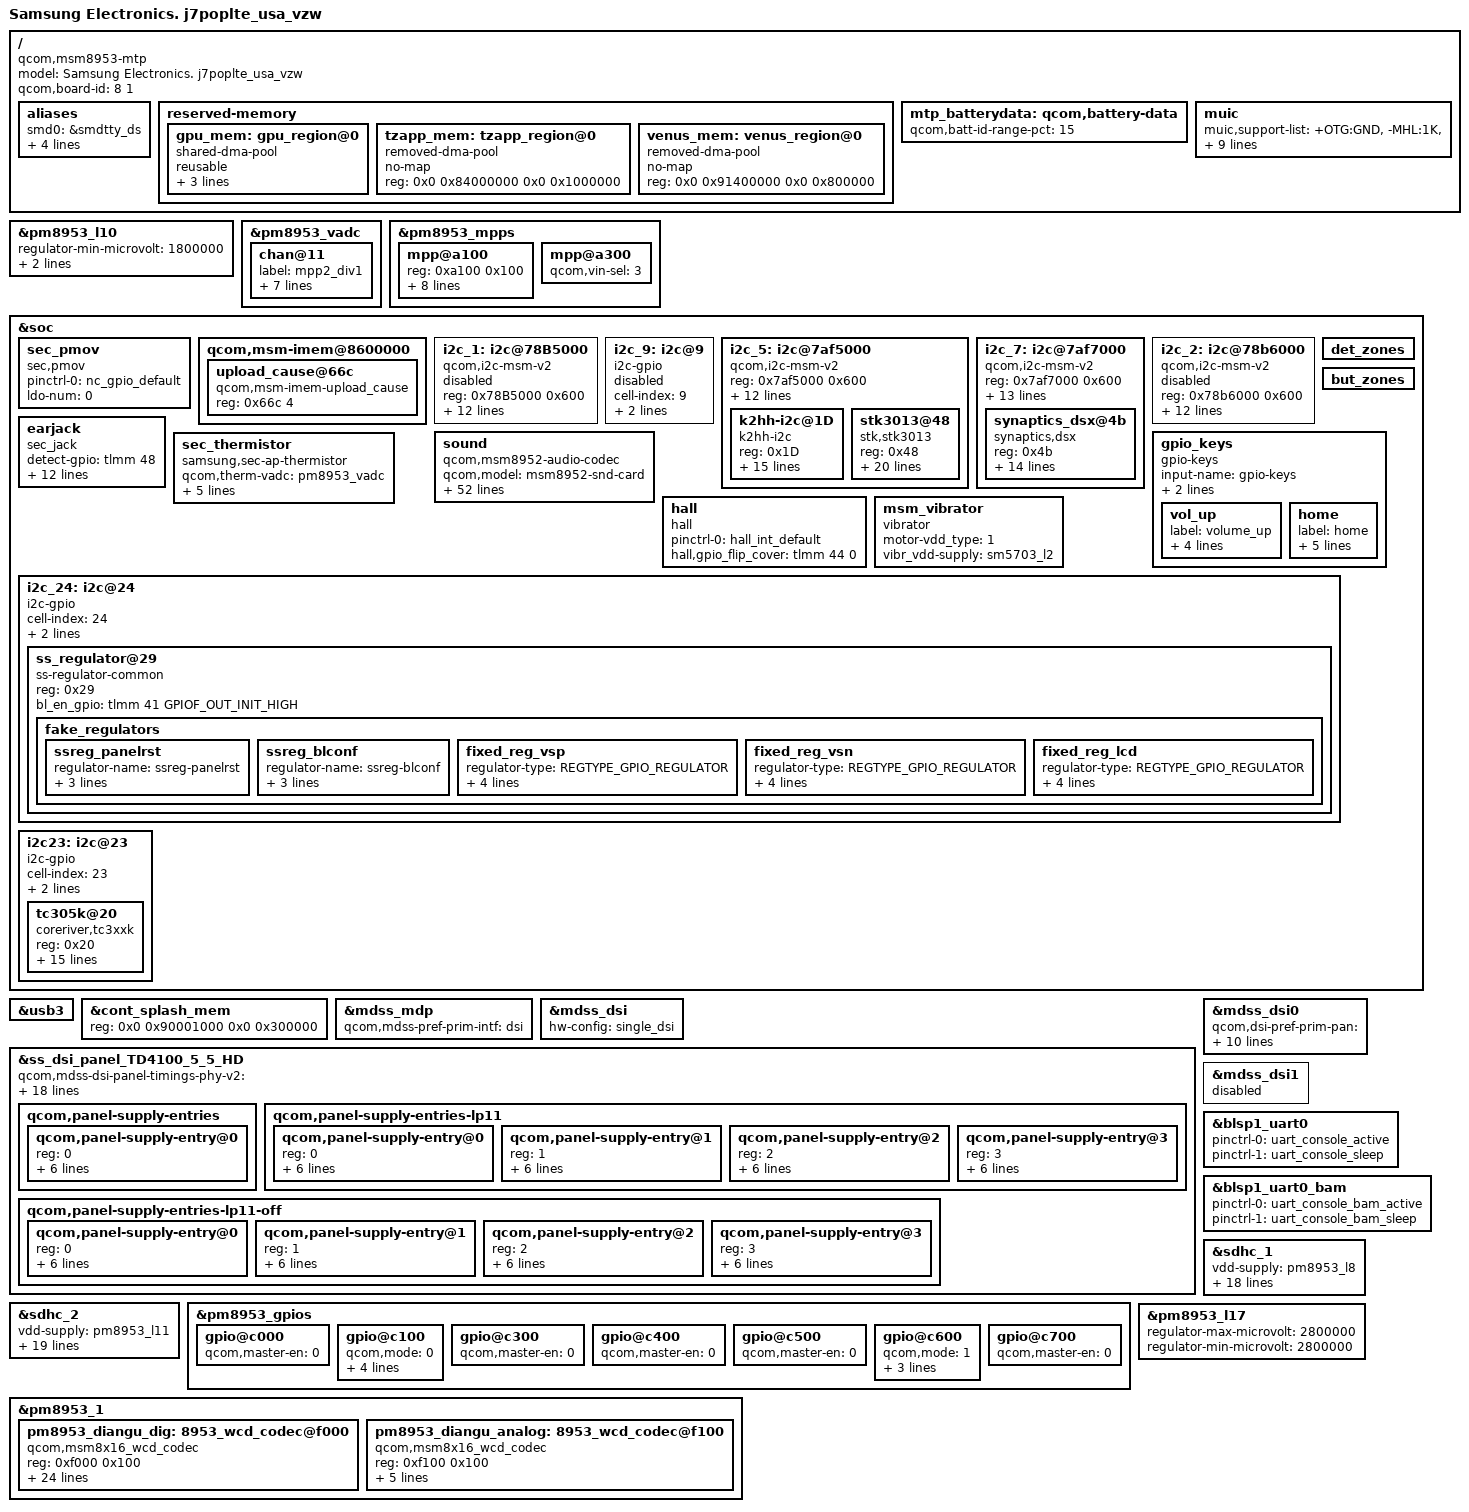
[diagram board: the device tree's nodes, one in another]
/*
 * Copyright (c) 2015, The Linux Foundation. All rights reserved.
 *
 * This program is free software; you can redistribute it and/or modify
 * it under the terms of the GNU General Public License version 2 and
 * only version 2 as published by the Free Software Foundation.
 *
 * This program is distributed in the hope that it will be useful,
 * but WITHOUT ANY WARRANTY; without even the implied warranty of
 * MERCHANTABILITY or FITNESS FOR A PARTICULAR PURPOSE.  See the
 * GNU General Public License for more details.
 */

/dts-v1/;

#include "../../qcom/msm8953.dtsi"
#include "msm-sec-audio.dtsi"
#include "msm8953-sec-common.dtsi"
#include "msm8953-sec-j7poplte_usa_vzw-pinctrl-r01.dtsi"
#include "msm8953-j7poplte_usa_vzw-sm5703.dtsi"
#include "msm8953-sec-j7poplte-battery-common-r01.dtsi"
#include "msm8953-camera-sensor-j7pop-usa_vzw-r01.dtsi"
#define GPIOF_DIR_OUT   (0 << 0)
#define GPIOF_INIT_HIGH (1 << 1)
#define GPIOF_OUT_INIT_HIGH     (GPIOF_DIR_OUT | GPIOF_INIT_HIGH)

#define REGTYPE_PANEL_RESET	0 /* control display reset */
#define REGTYPE_BL_CONFIG	1 /* BLIC initial configuration via I2c */
#define REGTYPE_GPIO_REGULATOR	2 /* GPIO regulator */
/ {
	model = "Samsung Electronics. j7poplte_usa_vzw";
	compatible = "qcom,msm8953-mtp", "qcom,msm8953", "qcom,mtp";
	qcom,board-id= <8 1>;
	aliases {
		/delete-property/ spi3;

		smd0 = &smdtty_ds;
		i2c1 = &i2c_1;
		i2c5 = &i2c_5;
		i2c7 = &i2c_7;
		i2c8 = &i2c_8;
	};

	reserved-memory {
		/delete-node/ gpu_region@0;
		gpu_mem: gpu_region@0 {
			compatible = "shared-dma-pool";
			reusable;
			alloc-ranges = <0x0 0x90000000 0x0 0x10000000>;
			alignment = <0 0x400000>;
			size = <0 0x800000>;
		};

		/delete-node/ tzapp_region@0;
		tzapp_mem: tzapp_region@0 {
			compatible = "removed-dma-pool";
			no-map;
			reg = <0x0 0x84000000 0x0 0x1000000>;
		};

		/delete-node/ venus_region@0;
		venus_mem: venus_region@0 {
			compatible = "removed-dma-pool";
			no-map;
			reg = <0x0 0x91400000 0x0 0x800000>;
		};
	};
};

&pm8953_l10 {
	status = "okay";
	regulator-min-microvolt = <1800000>;
	regulator-max-microvolt = <1800000>;
	qcom,init-voltage = <1800000>;
};

&pm8953_vadc {
	chan@11 {
		label = "mpp2_div1";
		reg = <0x11>;
		qcom,decimation = <0>;
		qcom,pre-div-channel-scaling = <0>;
		qcom,calibration-type = "absolute";
		qcom,scale-function = <0>;
		qcom,hw-settle-time = <5>;
		qcom,fast-avg-setup = <0>;
	};
};

&pm8953_mpps {
	mpp@a100 {
		reg = <0xa100 0x100>;
		qcom,pin-num = <2>;
		status = "okay";
		qcom,mode = <4>; /* AIN input */
		qcom,invert = <0>; /* Enable MPP */
		qcom,output-type = <0>; /* CMOS */
		qcom,ain-route = <1>; /* AMUX 6 */
		qcom,master-en = <0>;
		qcom,src-sel = <0>; /* Function constant */
		qcom,vin-sel = <3>;
	};
	mpp@a300 {
		qcom,vin-sel = <3>;
		status = "okay";
	};
};

&soc {
	sec_pmov {
		compatible = "sec,pmov";

		pinctrl-names = "default";
		pinctrl-0 = <&nc_gpio_default>;

		ldo-num = <0>;
		/*ldo0-supply = <&pm8953_l17>;
		 ldo1-supply = <&pm8953_lx>; */
	};

	qcom,msm-imem@8600000 {
		upload_cause@66c { /* CONFIG_SEC_DEBUG */
			compatible = "qcom,msm-imem-upload_cause";
			reg = <0x66c 4>;
		};
	};

	i2c_1: i2c@78B5000 { /* BLSP1 QUP0 */
		compatible = "qcom,i2c-msm-v2";
		#address-cells = <1>;
		#size-cells = <0>;
		reg-names = "qup_phys_addr";
		reg = <0x78B5000 0x600>;
		interrupt-names = "qup_irq";
		interrupts = <0 95 0>;
		qcom,clk-freq-out = <400000>;
		qcom,clk-freq-in  = <19200000>;
		clock-names = "iface_clk", "core_clk";
		clocks = <&clock_gcc clk_gcc_blsp1_ahb_clk>,
			<&clock_gcc clk_gcc_blsp1_qup1_i2c_apps_clk>;

		pinctrl-names = "i2c_active", "i2c_sleep";
		pinctrl-0 = <&i2c_1_active>;
		pinctrl-1 = <&i2c_1_sleep>;
		qcom,noise-rjct-scl = <0>;
		qcom,noise-rjct-sda = <0>;
		qcom,master-id = <86>;
		dmas = <&dma_blsp1 4 64 0x20000020 0x20>,
			<&dma_blsp1 5 32 0x20000020 0x20>;
		dma-names = "tx", "rx";
		status = "disabled";
	};

	i2c_9: i2c@9 { /* SW I2C */
		status = "disabled";
		cell-index = <9>;
		compatible = "i2c-gpio";
		gpios = <&tlmm 16 0 /* sda */
			&tlmm 17 0 /* scl */
		>;
		i2c-gpio,delay-us = <2>;
		#address-cells = <1>;
		#size-cells = <0>;
	};

	i2c_5: i2c@7af5000 { /* BLSP2 QUP1 */
		compatible = "qcom,i2c-msm-v2";
		#address-cells = <1>;
		#size-cells = <0>;
		reg-names = "qup_phys_addr";
		reg = <0x7af5000 0x600>;
		interrupt-names = "qup_irq";
		interrupts = <0 299 0>;
		qcom,clk-freq-out = <400000>;
		qcom,clk-freq-in  = <19200000>;
		clock-names = "iface_clk", "core_clk";
		clocks = <&clock_gcc clk_gcc_blsp2_ahb_clk>,
			<&clock_gcc clk_gcc_blsp2_qup1_i2c_apps_clk>;

		pinctrl-names = "i2c_active", "i2c_sleep";
		pinctrl-0 = <&i2c_5_active>;
		pinctrl-1 = <&i2c_5_sleep>;
		qcom,noise-rjct-scl = <0>;
		qcom,noise-rjct-sda = <0>;
		qcom,master-id = <84>;
		dmas = <&dma_blsp2 4 64 0x20000020 0x20>,
			<&dma_blsp2 5 32 0x20000020 0x20>;
		dma-names = "tx", "rx";

		k2hh-i2c@1D {
			compatible = "k2hh-i2c";
			reg = <0x1D>;
			pinctrl-names = "default", "sleep";
			pinctrl-0 = <&acc_sensor_int_active>;
			pinctrl-1 = <&acc_sensor_int_suspend>;
			interrupt-parent = <&tlmm>;
			interrupts = <42 0>;
			k2hh,irq_gpio = <&tlmm 42 0x00>;
			k2hh,vdd-supply = <&pm8953_l5>;
			k2hh,vio-supply = <&pm8953_l5>;
			k2hh,axis_map_x = <1>;
			k2hh,axis_map_y = <0>;
			k2hh,axis_map_z = <2>;
			k2hh,negate_x = <0>;
			k2hh,negate_y = <1>;
			k2hh,negate_z = <1>;
			k2hh,poll_interval = <100>;
			k2hh,min_interval = <2>;
		};

		stk3013@48 {
			compatible = "stk,stk3013";
			reg = <0x48>;
			pinctrl-names = "default", "sleep";
			pinctrl-0 = <&prox_sensor_int_active>;
			pinctrl-1 = <&prox_sensor_int_suspend>;
			interrupt-parent =  <&tlmm>;
			interrupts = <43 0>;
			stk,vdd-supply = <&sm5703_l3>;
			stk,vio-supply = <&pm8953_l5>;
			stk,irq-gpio = <&tlmm 43 0x00>;
			stk,state-reg = <0x2d>;
			stk,psctrl-reg = <0x71>;
			stk,alsctrl-reg = <0x2A>;
			stk,ledctrl-reg = <0xBF>;
			stk,wait-reg = <0x03>;
			stk,ps-thd-h = <20>;
			stk,ps-thd-l = <13>;
			stk,ps-cancel-thd-h = <10>;
			stk,ps-cancel-thd-l = <7>;
			stk,ps-cal-skip-adc = <10>;
			stk,ps-cal-fail-adc = <20>;
			stk,ps-default-offset = <3>;
			stk,transmittance = <500>;
		};

	};

	i2c_7: i2c@7af7000 { /* BLSP2 QUP3 */
		compatible = "qcom,i2c-msm-v2";
		#address-cells = <1>;
		#size-cells = <0>;
		reg-names = "qup_phys_addr";
		reg = <0x7af7000 0x600>;
		interrupt-names = "qup_irq";
		interrupts = <0 301 0>;
		qcom,master-id = <84>;
		qcom,clk-freq-out = <400000>;
		qcom,clk-freq-in  = <19200000>;
		clock-names = "iface_clk", "core_clk";
		clocks = <&clock_gcc clk_gcc_blsp2_ahb_clk>,
			<&clock_gcc clk_gcc_blsp2_qup3_i2c_apps_clk>;
		pinctrl-names = "i2c_active", "i2c_sleep";
		pinctrl-0 = <&i2c_7_active>;
		pinctrl-1 = <&i2c_7_suspend>;
		qcom,noise-rjct-scl = <0>;
		qcom,noise-rjct-sda = <0>;
		qcom,disable-dma;
		dmas = <&dma_blsp2 8 64 0x20000020 0x20>,
			<&dma_blsp2 9 32 0x20000020 0x20>;
		dma-names = "tx", "rx";
	};

	i2c_2: i2c@78b6000 { /* BLSP1 QUP2 */
		compatible = "qcom,i2c-msm-v2";
		#address-cells = <1>;
		#size-cells = <0>;
		reg-names = "qup_phys_addr";
		reg = <0x78b6000 0x600>;
		interrupt-names = "qup_irq";
		interrupts = <0 96 0>;
		qcom,clk-freq-out = <400000>;
		qcom,clk-freq-in  = <19200000>;
		clock-names = "iface_clk", "core_clk";
		clocks = <&clock_gcc clk_gcc_blsp1_ahb_clk>,
			<&clock_gcc clk_gcc_blsp1_qup2_i2c_apps_clk>;
		pinctrl-names = "i2c_active", "i2c_sleep";
		pinctrl-0 = <&i2c_2_active>;
		pinctrl-1 = <&i2c_2_sleep>;
		qcom,noise-rjct-scl = <0>;
		qcom,noise-rjct-sda = <0>;
		qcom,master-id = <86>;
		dmas = <&dma_blsp1 6 64 0x20000020 0x20>,
			<&dma_blsp1 7 32 0x20000020 0x20>;
		dma-names = "tx", "rx";
		status = "disabled";
	};

	det_zones: det_zones {
		#list-det-cells = <4>;
	};

	but_zones: but_zones {
		#list-but-cells = <3>;
	};

	earjack {
		compatible = "sec_jack";
		detect-gpio = <&tlmm 48 0x0>;
		key-gpio = <&tlmm 141 0x0>;
		det-dbtime = <100>;
		key-dbtime = <30>;

		det-zones-list = <&det_zones 0 10000 10 2>,
				 <&det_zones 910 10000 10 2>,
				 <&det_zones 1900 10000 10 1>,
				 <&det_zones 9999 10000 10 1>;
		but-zones-list = <&but_zones 226 0 310>, /* KEY_MEDIA:226 */
				 <&but_zones 582 311 350>, /* KEY_VOICECOMMAND:582 */
				 <&but_zones 115 351 470>, /* KEY_VOLUMEUP:115 */
				 <&but_zones 114 471 999>; /* KEY_VOLUMEDOWN:114 */

		pinctrl-names = "earjack_gpio_active",
				"earjack_gpio_suspend";
		pinctrl-0 = <&earjack_det_act &earjack_switch_act>;
		pinctrl-1 = <&earjack_det_sus &earjack_switch_sus>;
	};

	sound {
		status = "okay";
		compatible = "qcom,msm8952-audio-codec";
		qcom,model = "msm8952-snd-card";
		reg = <0xc051000 0x4>,
		      <0xc051004 0x4>,
		      <0xc055000 0x4>,
		      <0xc052000 0x4>;
		reg-names = "csr_gp_io_mux_mic_ctl",
			    "csr_gp_io_mux_spkr_ctl",
			    "csr_gp_io_lpaif_pri_pcm_pri_mode_muxsel",
			    "csr_gp_io_mux_quin_ctl";

		qcom,mpp-standalone-mode;
		qcom,mpp-channel-scaling = <2 1 1>;
		qcom,earjack-adc = <&pm8953_mpps 2 0>;
		qcom,earjack-read-vadc = <&pm8953_vadc>;
		qcom,msm-ext-pa = "primary";
		qcom,msm-mclk-freq = <9600000>;
		qcom,msm-hs-micbias-type = "internal";
		qcom,msm-micbias1-ext-cap;
		qcom,msm-micbias2-ext-cap;
		/delete-property/qcom,hdmi-dba-codec-rx;
		/delete-property/qcom,msm-mbhc-hphl-swh;
		/delete-property/qcom,msm-mbhc-gnd-swh;
		/delete-property/qcom,cdc-us-euro-gpios;
		qcom,audio-routing =
			"RX_BIAS", "MCLK",
			"SPK_RX_BIAS", "MCLK",
			"INT_LDO_H", "MCLK",
			"MIC BIAS External", "Handset Mic",
			"MIC BIAS External", "Secondary Mic",
			"AMIC1", "MIC BIAS External",
			"AMIC2", "Headset Mic",
			"AMIC3", "MIC BIAS External";

		qcom,msm-gpios =
			"pri_i2s";
		qcom,pinctrl-names =
			"all_off",
			"pri_i2s_act";
		pinctrl-names =
			"all_off",
			"pri_i2s_act";
		pinctrl-0 = <&cdc_pdm_lines_sus &cdc_pdm_lines_2_sus >;
		pinctrl-1 = <&cdc_pdm_lines_act &cdc_pdm_lines_2_act >;

		asoc-platform = <&pcm0>, <&pcm1>, <&pcm2>, <&voip>, <&voice>,
				<&loopback>, <&compress>, <&hostless>,
				<&afe>, <&lsm>, <&routing>, <&lpa>;
		asoc-platform-names = "msm-pcm-dsp.0", "msm-pcm-dsp.1",
				"msm-pcm-dsp.2", "msm-voip-dsp",
				"msm-pcm-voice", "msm-pcm-loopback",
				"msm-compress-dsp", "msm-pcm-hostless",
				"msm-pcm-afe", "msm-lsm-client",
				"msm-pcm-routing", "msm-pcm-lpa";
		asoc-cpu = <&dai_pri_auxpcm>,
				<&dai_mi2s0>, <&dai_mi2s1>,
				<&dai_mi2s2>, <&dai_mi2s3>,
				<&dai_mi2s5>, <&dai_mi2s6>,
				<&bt_sco_rx>, <&bt_sco_tx>,
				<&int_fm_rx>, <&int_fm_tx>,
				<&afe_pcm_rx>, <&afe_pcm_tx>,
				<&afe_proxy_rx>, <&afe_proxy_tx>,
				<&incall_record_rx>, <&incall_record_tx>,
				<&incall_music_rx>, <&incall_music_2_rx>;
		asoc-cpu-names = "msm-dai-q6-auxpcm.1",
				"msm-dai-q6-mi2s.0", "msm-dai-q6-mi2s.1",
				"msm-dai-q6-mi2s.2", "msm-dai-q6-mi2s.3",
				"msm-dai-q6-mi2s.5", "msm-dai-q6-mi2s.6",
				"msm-dai-q6-dev.12288", "msm-dai-q6-dev.12289",
				"msm-dai-q6-dev.12292", "msm-dai-q6-dev.12293",
				"msm-dai-q6-dev.224", "msm-dai-q6-dev.225",
				"msm-dai-q6-dev.241", "msm-dai-q6-dev.240",
				"msm-dai-q6-dev.32771", "msm-dai-q6-dev.32772",
				"msm-dai-q6-dev.32773", "msm-dai-q6-dev.32770";

		asoc-codec = <&stub_codec>, <&pm8953_diangu_dig>;
		asoc-codec-names = "msm-stub-codec.1", "cajon_codec";
	};

	gpio_keys {
		compatible = "gpio-keys";
		input-name = "gpio-keys";
		pinctrl-names = "tlmm_gpio_key_active","tlmm_gpio_key_suspend";
		pinctrl-0 = <&gpio_key_active>;
		pinctrl-1 = <&gpio_key_suspend>;

		vol_up {
			label = "volume_up";
			gpios = <&tlmm 85 0x1>;
			linux,input-type = <1>;
			linux,code = <115>;
			debounce-interval = <15>;
		};

		home {
			label = "home";
			gpios = <&tlmm 86 0x1>;
			linux,input-type = <1>;
			linux,code = <172>;
			gpio-key,wakeup;
			debounce-interval = <15>;
		};
	};

	sec_thermistor {
		compatible = "samsung,sec-ap-thermistor";
		qcom,therm-vadc = <&pm8953_vadc>;
		status = "okay";
		adc_channel = <19>;
		adc_array = <25977 26022 26068 26113 26158 26204 26246 26289 26332 26375
					26418 26471 26524 26577 26630 26683 26749 26815 26881 26947
					27013 27106 27199 27291 27384 27477 27582 27687 27792 27897
					28002 28113 28224 28335 28446 28558 28674 28790 28906 29023
					29139 29294 29449 29603 29758 29913 30091 30269 30447 30625
					30803 30982 31162 31342 31522 31702 31888 32074 32260 32446
					32632 32829 33026 33224 33421 33618 33841 34064 34286 34509
					34732 34947 35162 35376 35591 35806 36012 36217 36423 36628
					36834 37010 37185 37361 37537 37713 37919 38126 38332 38539
					38745 38892 39038 39185 39331 39478 39628 39779 39930 40081
					40232 40324 40416 40508 40600 40692 40737 40782 40827 40872
					40917>;

		temp_array = <900 890 880 870 860 850 840 830 820 810
			800 790 780 770 760 750 740 730 720 710
			700 690 680 670 660 650 640 630 620 610
			600 590 580 570 560 550 540 530 520 510
			500 490 480 470 460 450 440 430 420 410
			400 390 380 370 360 350 340 330 320 310
			300 290 280 270 260 250 240 230 220 210
			200 190 180 170 160 150 140 130 120 110
			100 90 80 70 60 50 40 30 20 10
			0 (-10) (-20) (-30) (-40) (-50) (-60) (-70) (-80) (-90)
			(-100) (-110) (-120) (-130) (-140) (-150) (-160) (-170) (-180) (-190)
			(-200)>;
	};

	hall {
		compatible = "hall";
		status = "okay";
		pinctrl-names = "default";
		pinctrl-0 = <&hall_int_default>;
		hall,gpio_flip_cover = <&tlmm 44 0>;
	};

	msm_vibrator {
		compatible = "vibrator";
		motor-vdd_type = <1>; /* 0: gpio, 1: pmic */
		vibr_vdd-supply = <&sm5703_l2>;
	};
};

&usb3 {
	/delete-property/ vbus_dwc3-supply;
};

#include "../../qcom/msm8953-mdss-panels.dtsi"
#include "../../../../../../drivers/video/msm/mdss/samsung/TD4100_5_5/dsi_panel_TD4100_5_5_hd_video.dtsi"
#include "../../../../../../drivers/video/msm/mdss/samsung/PBA_BOOTING_HD/dsi_panel_PBA_BOOTING_hd_video.dtsi"

&cont_splash_mem {
	reg = <0x0 0x90001000 0x0 0x300000>; /*720*1280*3=2.76M =>3M*/
};

&mdss_mdp {
	qcom,mdss-pref-prim-intf = "dsi";
};

&mdss_dsi {
	hw-config = "single_dsi";
};
/* Unnecessary values for fixed reuglator,
 * but required by mdss_dsi_get_dt_vreg_data().
 */
#define DEFAULT_FIXED_VAL	0
&ss_dsi_panel_TD4100_5_5_HD {
	qcom,panel-supply-entries {
		#address-cells = <1>;
		#size-cells = <0>;

		/* VDD_LCD_1P8 */

		qcom,panel-supply-entry@0 {
			reg = <0>;
			qcom,supply-name = "vddlcd";
			qcom,supply-min-voltage = <DEFAULT_FIXED_VAL>;
			qcom,supply-max-voltage = <DEFAULT_FIXED_VAL>;
			qcom,supply-enable-load = <DEFAULT_FIXED_VAL>;
			qcom,supply-disable-load = <DEFAULT_FIXED_VAL>;
			qcom,supply-post-on-sleep = <0>;
		};
		/*
		qcom,panel-supply-entry@1 {
			reg = <1>;
			qcom,supply-name = "vddtsp";
			qcom,supply-min-voltage = <DEFAULT_FIXED_VAL>;
			qcom,supply-max-voltage = <DEFAULT_FIXED_VAL>;
			qcom,supply-enable-load = <DEFAULT_FIXED_VAL>;
			qcom,supply-disable-load = <DEFAULT_FIXED_VAL>;
			qcom,supply-post-on-sleep = <3>;
		};
		*/
	};
	qcom,panel-supply-entries-lp11 {
		#address-cells = <1>;
		#size-cells = <0>;

		qcom,panel-supply-entry@0 {
			reg = <0>;
			qcom,supply-name = "blconf";
			qcom,supply-min-voltage = <DEFAULT_FIXED_VAL>;
			qcom,supply-max-voltage = <DEFAULT_FIXED_VAL>;
			qcom,supply-enable-load = <DEFAULT_FIXED_VAL>;
			qcom,supply-disable-load = <DEFAULT_FIXED_VAL>;
			qcom,supply-post-on-sleep = <0>;
		};

		qcom,panel-supply-entry@1 {
			reg = <1>;
			qcom,supply-name = "vsp";
			qcom,supply-min-voltage = <DEFAULT_FIXED_VAL>;
			qcom,supply-max-voltage = <DEFAULT_FIXED_VAL>;
			qcom,supply-enable-load = <DEFAULT_FIXED_VAL>;
			qcom,supply-disable-load = <DEFAULT_FIXED_VAL>;
			qcom,supply-post-on-sleep = <0>;
		};

		qcom,panel-supply-entry@2 {
			reg = <2>;
			qcom,supply-name = "vsn";
			qcom,supply-min-voltage = <DEFAULT_FIXED_VAL>;
			qcom,supply-max-voltage = <DEFAULT_FIXED_VAL>;
			qcom,supply-enable-load = <DEFAULT_FIXED_VAL>;
			qcom,supply-disable-load = <DEFAULT_FIXED_VAL>;
			qcom,supply-post-on-sleep = <6>;
		};

		qcom,panel-supply-entry@3 {
			reg = <3>;
			qcom,supply-name = "panelrst";
			qcom,supply-min-voltage = <DEFAULT_FIXED_VAL>;
			qcom,supply-max-voltage = <DEFAULT_FIXED_VAL>;
			qcom,supply-enable-load = <DEFAULT_FIXED_VAL>;
			qcom,supply-disable-load = <DEFAULT_FIXED_VAL>;
			qcom,supply-post-on-sleep = <0>;
		};
	};

	qcom,panel-supply-entries-lp11-off {
		#address-cells = <1>;
		#size-cells = <0>;

		qcom,panel-supply-entry@0 {
			reg = <0>;
			qcom,supply-name = "panelrst";
			qcom,supply-min-voltage = <DEFAULT_FIXED_VAL>;
			qcom,supply-max-voltage = <DEFAULT_FIXED_VAL>;
			qcom,supply-enable-load = <DEFAULT_FIXED_VAL>;
			qcom,supply-disable-load = <DEFAULT_FIXED_VAL>;
			qcom,supply-post-off-sleep = <1>;
		};

		qcom,panel-supply-entry@1 {
			reg = <1>;
			qcom,supply-name = "blconf";
			qcom,supply-min-voltage = <DEFAULT_FIXED_VAL>;
			qcom,supply-max-voltage = <DEFAULT_FIXED_VAL>;
			qcom,supply-enable-load = <DEFAULT_FIXED_VAL>;
			qcom,supply-disable-load = <DEFAULT_FIXED_VAL>;
			qcom,supply-post-off-sleep = <0>;
		};

		qcom,panel-supply-entry@2 {
			reg = <2>;
			qcom,supply-name = "vsp";
			qcom,supply-min-voltage = <DEFAULT_FIXED_VAL>;
			qcom,supply-max-voltage = <DEFAULT_FIXED_VAL>;
			qcom,supply-enable-load = <DEFAULT_FIXED_VAL>;
			qcom,supply-disable-load = <DEFAULT_FIXED_VAL>;
			qcom,supply-post-off-sleep = <6>;
		};

		qcom,panel-supply-entry@3 {
			reg = <3>;
			qcom,supply-name = "vsn";
			qcom,supply-min-voltage = <DEFAULT_FIXED_VAL>;
			qcom,supply-max-voltage = <DEFAULT_FIXED_VAL>;
			qcom,supply-enable-load = <DEFAULT_FIXED_VAL>;
			qcom,supply-disable-load = <DEFAULT_FIXED_VAL>;
			qcom,supply-post-off-sleep = <6>;
		};
	};
};

&mdss_dsi0 {
	/delete-property/ vdd-supply;
	/delete-property/ lab-supply;
	/delete-property/ ibb-supply;
	qcom,dsi-pref-prim-pan = <&ss_dsi_panel_TD4100_5_5_HD>;
	pinctrl-names = "mdss_default", "mdss_sleep";
	pinctrl-0 = <&mdss_dsi_active &mdss_dsi_esd_active &mdss_dsi_blic_active>;
	pinctrl-1 = <&mdss_dsi_suspend &mdss_dsi_esd_suspend &mdss_dsi_blic_suspend>;

	vddlcd-supply = <&fixed_reg_lcd>; /* 1.8V */
	panelrst-supply = <&ssreg_panelrst>;
	blconf-supply = <&ssreg_blconf>;
	vsp-supply = <&fixed_reg_vsp>;
	vsn-supply = <&fixed_reg_vsn>;
};

&mdss_dsi1 {
	/delete-property/ vdd-supply;
	/delete-property/ lab-supply;
	/delete-property/ ibb-supply;
	status = "disabled";
};

&ss_dsi_panel_TD4100_5_5_HD {
	qcom,mdss-dsi-panel-timings-phy-v2 = [	/* MSM8953 */
		21 1E 06 07 04 03 04 a0				/* Data 0 */
		21 1E 06 07 04 03 04 a0				/* Data 1 */
		21 1E 06 07 04 03 04 a0				/* Data 2 */
		21 1E 06 07 04 03 04 a0				/* Data 3 */
		21 15 06 07 04 03 04 a0				/* Clk lane */
	];
	qcom,mdss-dsi-h-back-porch = <164>;
	qcom,mdss-dsi-h-front-porch = <252>;
	qcom,mdss-dsi-h-pulse-width = <4>;
	qcom,mdss-dsi-h-sync-skew = <0>;
	qcom,mdss-dsi-v-back-porch = <125>;
	qcom,mdss-dsi-v-front-porch = <127>;
	qcom,mdss-dsi-v-pulse-width = <127>;
	qcom,mdss-dsi-t-clk-post = <0x0C>;
	qcom,mdss-dsi-t-clk-pre = <0x28>;
	qcom,mdss-dsi-panel-clockrate = <684000000>;

	qcom,esd-check-enabled;
	qcom,mdss-dsi-panel-status-check-mode ="reg_read_irq";
	qcom,mdss-dsi-panel-status-value=<1>;
	qcom,mdss-dsi-panel-status-irq-trigger1 = "falling";
	samsung,esd-irq-gpio1 = <&tlmm 13 0>;
};

&soc {
	i2c_24: i2c@24 {

		cell-index = <24>;
		compatible = "i2c-gpio";
		gpios = <&tlmm 14 0 /* sda */
			&tlmm 15 0 /* scl */
			>;
		i2c-gpio,delay-us = <2>;

		ss_regulator@29 {
			compatible = "ss-regulator-common";
			reg = <0x29>;

			/* BLIC enable pin */
			bl_en_gpio = <&tlmm 41 GPIOF_OUT_INIT_HIGH>;

			fake_regulators {
				/* control display reset sequence */
				ssreg_panelrst: ssreg_panelrst {
					/* Do not put regulator-boot-on in fake_reg_reset.
					 * It will call reset sequence in kernel booting,
					 * and causes display off.
					 */
					regulator-name = "ssreg-panelrst";
					regulator-type = <REGTYPE_PANEL_RESET>;

					panel-rst-seq = <1 1>, <0 1>, <1 0>;
					rst-gpio = <&tlmm 50 GPIOF_OUT_INIT_HIGH>;
				};

				/* configure BLIC initdata via I2C */
				ssreg_blconf: ssreg_blconf {
					regulator-name = "ssreg-blconf";
					regulator-type = <REGTYPE_BL_CONFIG>;

					init_data = [
					/* i2c:	addr		data */
						01		00
						02		BF
						03		02
						04		0A
						05		0A
						06		F4
						10		FF
						11		07
						12		BF
						13		80
						14		FD
						16		F5
						17		8D
					];
				};
				/* VSP 5.4V */
				fixed_reg_vsp: fixed_reg_vsp {
					 regulator-type = <REGTYPE_GPIO_REGULATOR>;
					 status = "okay";
					 regulator-name = "fixed_reg_gpio22";
					 gpio = <&tlmm 22 0>; // PANEL_ENP
					 enable-active-high;
					 regulator-boot-on;
				};

				/* VSN -5.4V */
				fixed_reg_vsn: fixed_reg_vsn {
					 regulator-type = <REGTYPE_GPIO_REGULATOR>;
					 status = "okay";
					 regulator-name = "fixed_reg_gpio23";
					 gpio = <&tlmm 23 0>; // PANEL_ENN
					 enable-active-high;
					 regulator-boot-on;
				};


				fixed_reg_lcd: fixed_reg_lcd {
					 regulator-type = <REGTYPE_GPIO_REGULATOR>;
					 status = "okay";
					 regulator-name = "fixed_reg_gpio94";
					 gpio = <&tlmm 94 0>;
					 enable-active-high;
					 regulator-boot-on;
				};
			/*
				fixed_reg_tsp: fixed_reg_tsp {
					 regulator-type = <REGTYPE_GPIO_REGULATOR>;
					 status = "okay";
					 regulator-name = "fixed_reg_gpio91";
					 gpio = <&tlmm 91 0>;
					 enable-active-high;
					 regulator-boot-on;
				};
			*/
			};
		};
	};



	i2c_7: i2c@7af7000 { /* BLSP2 QUP3 */
		synaptics_dsx@4b {
			compatible = "synaptics,dsx";
			reg = <0x4b>;
			pinctrl-names = "default";
			pinctrl-0 = <&tsp_int_active>;
			interrupt-parent = <&tlmm>;
			interrupts = <59 0>;
			synaptics,irq_gpio = <&tlmm 59 0>;
			synaptics,irq_type = <8200>;
			synaptics,max_coords = <720 1280>;
			synaptics,num_lines = <32 18>;
			synaptics,project_name = "J7pop", "G727";
			synaptics,ub-i2c-addr = <0x2c>;
			synaptics,reset-delay-ms = <150>;
			synaptics,firmware_name = "tsp_synaptics/td4100_j7pop.fw";
			synaptics,firmware_name_bl = "tsp_synaptics/td4100_j7pop_recovery.fw";
		};
	};

	i2c23: i2c@23 { /* SW I2C */
		cell-index = <23>;
		compatible = "i2c-gpio";
		gpios = <&tlmm 16 0 /* sda */
			&tlmm 17 0 /* scl */
			>;
		i2c-gpio,delay-us = <1>;
		#address-cells = <1>;
		#size-cells = <0>;

		tc305k@20{
			compatible = "coreriver,tc3xxk";
			reg = <0x20>;
			interrupt-parent = <&tlmm>;
			interrupts = <60 0>;
			pinctrl-names = "default", "idle", "sleep";
			pinctrl-0 = <&touchkey_i2c_active &touchkey_int_active>;
			pinctrl-1 = <&touchkey_i2c_active &touchkey_int_active>;
			pinctrl-2 = <&touchkey_i2c_suspend &touchkey_int_suspend>;
			coreriver,fw-name = "tk_coreriver/tc305k_j7pop.fw";
			coreriver,sda-gpio = <&tlmm 16 0>;
			coreriver,scl-gpio = <&tlmm 17 0>;
			coreriver,irq-gpio = <&tlmm 60 0>;
			coreriver,power-gpio = <&tlmm 132 0>;
			coreriver,sensing-ch-num = <0x4>;
		};
	};


};

&blsp1_uart0 {
	status = "ok";
	pinctrl-names = "default", "sleep";
	pinctrl-0 = <&uart_console_active>;
	pinctrl-1 = <&uart_console_sleep>;
};

&blsp1_uart0_bam {
	status = "ok";
	pinctrl-names = "default", "sleep";
	pinctrl-0 = <&uart_console_bam_active>;
	pinctrl-1 = <&uart_console_bam_sleep>;
};

&sdhc_1 {
	/* device core power supply */
	vdd-supply = <&pm8953_l8>;
	qcom,vdd-always-on;
	qcom,vdd-lpm-sup;
	qcom,vdd-voltage-level = <2900000 2900000>;
	qcom,vdd-current-level = <200 570000>;

	/* device communication power supply */
	vdd-io-supply = <&pm8953_l5>;
	qcom,vdd-io-always-on;
	qcom,vdd-io-lpm-sup;
	qcom,vdd-io-voltage-level = <1800000 1800000>;
	qcom,vdd-io-current-level = <200 325000>;

	pinctrl-names = "active", "sleep";
	pinctrl-0 = <&sdc1_clk_on &sdc1_cmd_on &sdc1_data_on  &sdc1_rclk_on>;
	pinctrl-1 = <&sdc1_clk_off &sdc1_cmd_off &sdc1_data_off &sdc1_rclk_off>;

	qcom,clk-rates = <400000 20000000 25000000 50000000 100000000 192000000
								384000000>;
	qcom,nonremovable;
	qcom,bus-speed-mode = "HS400_1p8v", "HS200_1p8v", "DDR_1p8v";

	status = "ok";
};

&sdhc_2 {
	/* device core power supply */
	vdd-supply = <&pm8953_l11>;
	qcom,vdd-voltage-level = <2950000 2950000>;
	qcom,vdd-current-level = <15000 800000>;

	/* device communication power supply */
	vdd-io-supply = <&pm8953_l12>;
	qcom,vdd-io-voltage-level = <1800000 2950000>;
	qcom,vdd-io-current-level = <200 22000>;

	pinctrl-names = "active", "sleep";
	pinctrl-0 = <&sdc2_clk_on &sdc2_cmd_on &sdc2_data_on &sdc2_cd_on>;
	pinctrl-1 = <&sdc2_clk_off &sdc2_cmd_off &sdc2_data_off &sdc2_cd_off>;

	#address-cells = <0>;
	interrupt-parent = <&sdhc_2>;
	interrupts = <0 1 2>;
	#interrupt-cells = <1>;
	interrupt-map-mask = <0xffffffff>;
	interrupt-map = <0 &intc 0 125 0
		1 &intc 0 221 0
		2 &tlmm 133 0>;
	interrupt-names = "hc_irq", "pwr_irq", "status_irq";
	cd-gpios = <&tlmm 133 0x1>;

	qcom,clk-rates = <400000 20000000 25000000 50000000 100000000
								192000000>;
	qcom,bus-speed-mode = "SDR12", "SDR25", "SDR50", "DDR50", "SDR104";

	status = "ok";
};

/{
	mtp_batterydata: qcom,battery-data {
		qcom,batt-id-range-pct = <15>;
		#include "../../qcom/batterydata-itech-3000mah.dtsi"
		#include "../../qcom/batterydata-ascent-3450mAh.dtsi"
	};
};

&pm8953_gpios {
	/* GPIO 1*/
	gpio@c000 {
		qcom,master-en = <0>;
		status = "okay";
	};
	/* GPIO 2 (NFC_CLK_REQ) */
	gpio@c100 {
		qcom,mode = <0>;
		qcom,pull = <4>;
		qcom,vin-sel = <3>;	/* 1.8V*/
		qcom,src-sel = <0>; /*src-sel has no matter when mode is input*/
		qcom,master-en = <1>;
		status = "okay";
	};
	/* GPIO 4*/
	gpio@c300 {
		qcom,master-en = <0>;
		status = "okay";
	};
	/* GPIO 5*/
	gpio@c400 {
		qcom,master-en = <0>;
		status = "okay";
	};
	/* GPIO 6*/
	gpio@c500 {
		qcom,master-en = <0>;
		status = "okay";
	};
	/* GPIO 7 */
	gpio@c600 {
		qcom,mode = <1>;
		qcom,pull = <5>;
		qcom,vin-sel = <3>;	/* 1.8V*/
		qcom,master-en = <1>;
		status = "okay";
	};
	/* GPIO 8 */
	gpio@c700 {
		qcom,master-en = <0>;
		status = "okay";
	};
};

&pm8953_l17 {
    regulator-max-microvolt = <2800000>;
    regulator-min-microvolt = <2800000>;
};

/ {
	muic {
		status = "okay";
		muic,support-list = "+OTG:GND",
			"-MHL:1K",
			"-VZW Accessory:28.7K",
			"+VZW Incompatible:34K",
			"-Smartdock:40.2K",
			"-HMT:49.9K",
			"-Audiodock:64.9K",
			"-USB LANHUB:80.07K",
			"+Charging Cable:102K",
			"-Game Pad:121K",
			"+Jig USB Off:255K",
			"+Jig USB On:301K",
			"+Deskdock:365K",
			"+TYPE2 Charger:442K",
			"+Jig UART Off:523K",
			"+Jig UART On:619K",
			"+TA:OPEN",
			"+USB:OPEN",
			"+CDP:OPEN",
			"+Undefined Charging:XXX";
	};
};

&pm8953_1 {
	pm8953_diangu_dig: 8953_wcd_codec@f000 {
		compatible = "qcom,msm8x16_wcd_codec";
		reg = <0xf000 0x100>;
		interrupt-parent = <&spmi_bus>;
		interrupts = <0x1 0xf0 0x0>,
			     <0x1 0xf0 0x1>,
			     <0x1 0xf0 0x2>,
			     <0x1 0xf0 0x3>,
			     <0x1 0xf0 0x4>,
			     <0x1 0xf0 0x5>,
			     <0x1 0xf0 0x6>,
			     <0x1 0xf0 0x7>;
		interrupt-names = "spk_cnp_int",
				  "spk_clip_int",
				  "spk_ocp_int",
				  "ins_rem_det1",
				  "but_rel_det",
				  "but_press_det",
				  "ins_rem_det",
				  "mbhc_int";

		cdc-vdda-cp-supply = <&pm8953_s4>;
		qcom,cdc-vdda-cp-voltage = <1900000 2050000>;
		qcom,cdc-vdda-cp-current = <500000>;

		cdc-vdd-io-supply = <&pm8953_l5>;
		qcom,cdc-vdd-io-voltage = <1800000 1800000>;
		qcom,cdc-vdd-io-current = <5000>;

		cdc-vdd-pa-supply = <&pm8953_s4>;
		qcom,cdc-vdd-pa-voltage = <1900000 2050000>;
		qcom,cdc-vdd-pa-current = <260000>;

		cdc-vdd-mic-bias-supply = <&pm8953_l13>;
		qcom,cdc-vdd-mic-bias-voltage = <3125000 3125000>;
		qcom,cdc-vdd-mic-bias-current = <5000>;

		qcom,cdc-mclk-clk-rate = <9600000>;
		qcom,cdc-micbias-cfilt-mv = <2800000>;

		qcom,cdc-static-supplies =  "cdc-vdd-io",
					   "cdc-vdd-pa",
					   "cdc-vdda-cp";

		qcom,cdc-on-demand-supplies = "cdc-vdd-mic-bias";
		qcom,dig-cdc-base-addr = <0xc0f0000>;

		qcom,tx2n_to_hph_ref; /* 0x143, bit[2]:1 */
		qcom,ext_pullup_imp; /* 0x143, bit[4]:0 */
	};

	pm8953_diangu_analog: 8953_wcd_codec@f100 {
		compatible = "qcom,msm8x16_wcd_codec";
		reg = <0xf100 0x100>;
		interrupt-parent = <&spmi_bus>;
		interrupts = <0x1 0xf1 0x0>,
			     <0x1 0xf1 0x1>,
			     <0x1 0xf1 0x2>,
			     <0x1 0xf1 0x3>,
			     <0x1 0xf1 0x4>,
			     <0x1 0xf1 0x5>;
		interrupt-names = "ear_ocp_int",
				  "hphr_ocp_int",
				  "hphl_ocp_det",
				  "ear_cnp_int",
				  "hphr_cnp_int",
				  "hphl_cnp_int";
		qcom,dig-cdc-base-addr = <0xc0f0000>;
	};
};
